# K1921VK01T register map
Vendor: NIIET; Series: K1921VKx; File version: 2.2
CPU: CM4 r0p1, little endian, MPU, FPU, 3 interrupt priority bits
Registers are 32-bit, read-write, reset 0x0 unless marked. A register's access mark holds for its fields unless they carry their own. Offsets are from the block's base; [hi:lo] are bit positions; {n}, {i} and the like mark numbered series; 'fields as' and 'values as' point back to an identical list.

## NT_COMMON_REG — Common block registers
Base 0x80030000
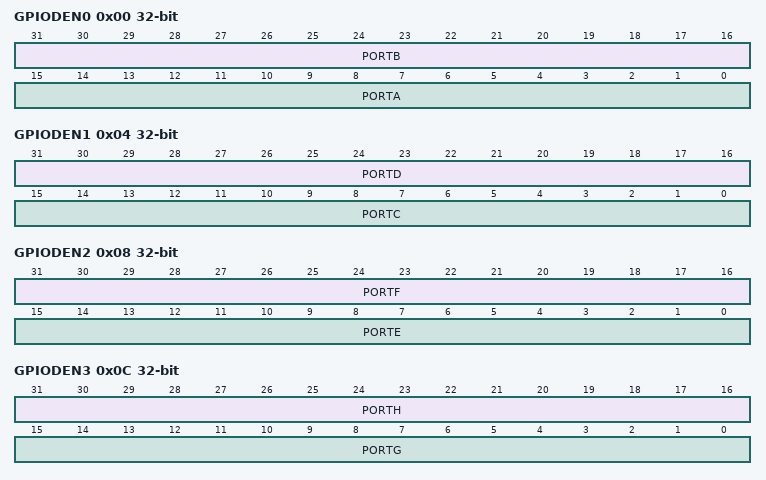
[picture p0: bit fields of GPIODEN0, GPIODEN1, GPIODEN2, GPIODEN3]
0x00 GPIODEN0 — Port A,B digital enable register
  [31:16] PORTB — Port B digital output (GPIO or ALTFUNC) enable
  [15:0] PORTA — Port A digital output (GPIO or ALTFUNC) enable
0x00 GPIODENA 16-bit (alternate view of GPIODEN0) — Port A digital enable register
  [15:0] PORTA — Port A digital output (GPIO or ALTFUNC) enable
0x02 GPIODENB 16-bit (alternate view of GPIODEN0) — Port B digital enable register
  [15:0] PORTB — Port B digital output (GPIO or ALTFUNC) enable
0x04 GPIODEN1 — Port C,D digital enable register
  [31:16] PORTD — Port D digital output (GPIO or ALTFUNC) enable
  [15:0] PORTC — Port C digital output (GPIO or ALTFUNC) enable
0x04 GPIODENC 16-bit (alternate view of GPIODEN1) — Port C digital enable register
  [15:0] PORTC — Port C digital output (GPIO or ALTFUNC) enable
0x06 GPIODEND 16-bit (alternate view of GPIODEN1) — Port D digital enable register
  [15:0] PORTD — Port D digital output (GPIO or ALTFUNC) enable
0x08 GPIODEN2 — Port E,F digital enable register
  [31:16] PORTF — Port F digital output (GPIO or ALTFUNC) enable
  [15:0] PORTE — Port E digital output (GPIO or ALTFUNC) enable
0x08 GPIODENE 16-bit (alternate view of GPIODEN2) — Port E digital enable register
  [15:0] PORTE — Port E digital output (GPIO or ALTFUNC) enable
0x0A GPIODENF 16-bit (alternate view of GPIODEN2) — Port F digital enable register
  [15:0] PORTF — Port F digital output (GPIO or ALTFUNC) enable
0x0C GPIODEN3 — Port G,H digital enable register
  [31:16] PORTH — Port H digital output (GPIO or ALTFUNC) enable
  [15:0] PORTG — Port G digital output (GPIO or ALTFUNC) enable
0x0C GPIODENG 16-bit (alternate view of GPIODEN3) — Port G digital enable register
  [15:0] PORTG — Port G digital output (GPIO or ALTFUNC) enable
0x0E GPIODENH 16-bit (alternate view of GPIODEN3) — Port H digital enable register
  [15:0] PORTH — Port H digital output (GPIO or ALTFUNC) enable
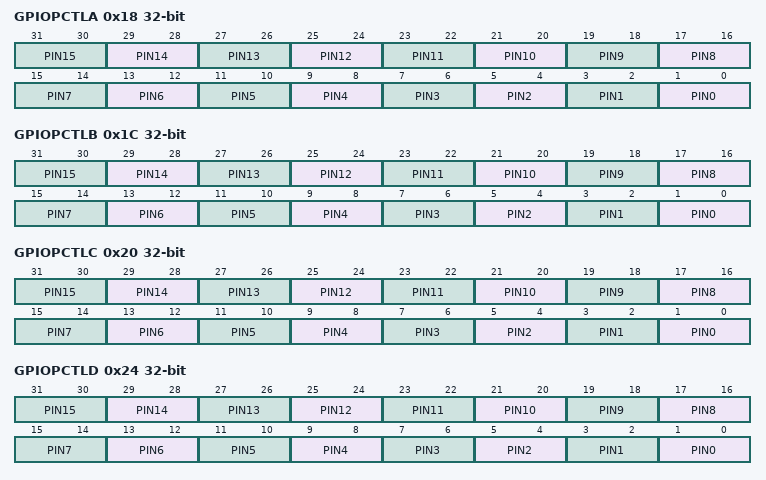
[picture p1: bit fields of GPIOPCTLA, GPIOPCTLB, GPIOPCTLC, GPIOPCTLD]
0x18 GPIOPCTLA — Port A alternative function selection register
  [all] fields
    0=AltFunc1 (first alternative function for pin); 1=AltFunc2 (second alternative function for pin); 2=AltFunc3 (third alternative function for pin)
  [2n+1:2n] PIN{n} (n=0..15) — Pin A{n} alternative function selection
0x1C GPIOPCTLB — Port B alternative function selection register
  [all] fields
    values as the fields of GPIOPCTLA
  [2n+1:2n] PIN{n} (n=0..15) — Pin B{n} alternative function selection
0x20 GPIOPCTLC — Port C alternative function selection register
  [all] fields
    values as the fields of GPIOPCTLA
  [2n+1:2n] PIN{n} (n=0..15) — Pin C{n} alternative function selection
0x24 GPIOPCTLD — Port D alternative function selection register
  [all] fields
    values as the fields of GPIOPCTLA
  [2n+1:2n] PIN{n} (n=0..15) — Pin D{n} alternative function selection
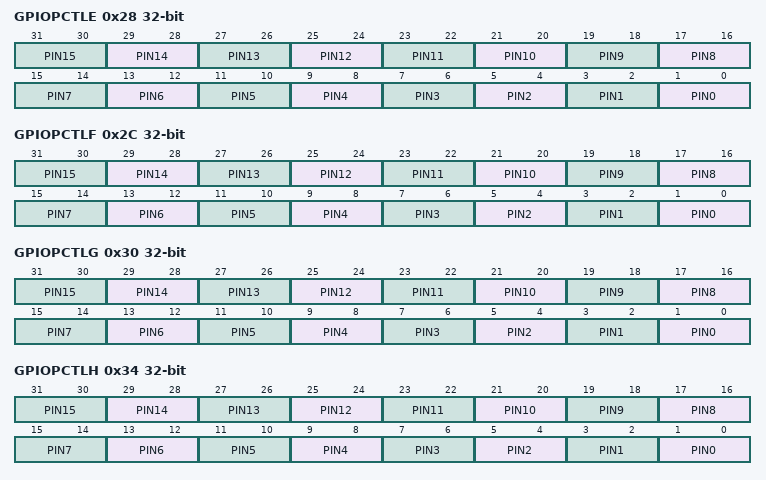
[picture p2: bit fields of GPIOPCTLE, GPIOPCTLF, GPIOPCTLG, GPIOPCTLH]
0x28 GPIOPCTLE — Port E alternative function selection register
  [all] fields
    values as the fields of GPIOPCTLA
  [2n+1:2n] PIN{n} (n=0..15) — Pin E{n} alternative function selection
0x2C GPIOPCTLF — Port F alternative function selection register
  [all] fields
    values as the fields of GPIOPCTLA
  [2n+1:2n] PIN{n} (n=0..15) — Pin F{n} alternative function selection
0x30 GPIOPCTLG — Port G alternative function selection register
  [all] fields
    values as the fields of GPIOPCTLA
  [2n+1:2n] PIN{n} (n=0..15) — Pin G{n} alternative function selection
0x34 GPIOPCTLH — Port H alternative function selection register
  [all] fields
    values as the fields of GPIOPCTLA
  [2n+1:2n] PIN{n} (n=0..15) — Pin H{n} alternative function selection
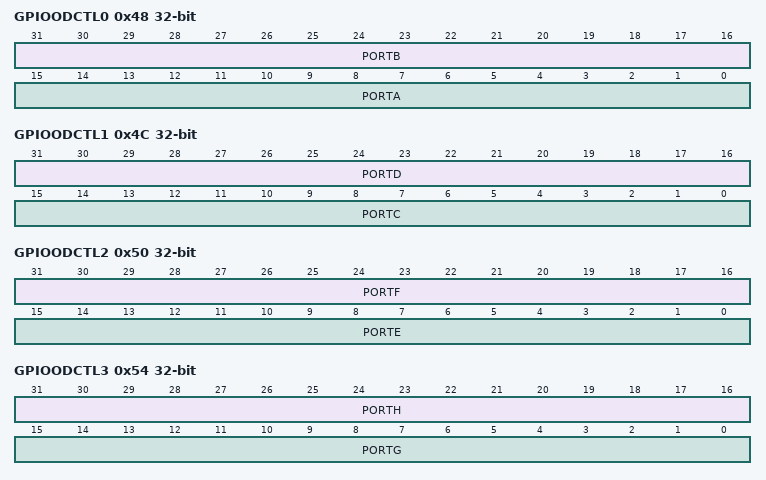
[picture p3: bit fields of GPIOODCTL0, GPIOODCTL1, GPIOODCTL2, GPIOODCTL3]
0x48 GPIOODCTL0 — Port A,B open-drain enable register
  [31:16] PORTB — Port B open-drain enable
  [15:0] PORTA — Port A open-drain enable
0x48 GPIOODCTLA 16-bit (alternate view of GPIOODCTL0) — Port A open-drain enable register
  [15:0] PORTA — Port A open-drain enable
0x4A GPIOODCTLB 16-bit (alternate view of GPIOODCTL0) — Port B open-drain enable register
  [15:0] PORTB — Port B open-drain enable
0x4C GPIOODCTL1 — Port C,D open-drain enable register
  [31:16] PORTD — Port D open-drain enable
  [15:0] PORTC — Port C open-drain enable
0x4C GPIOODCTLC 16-bit (alternate view of GPIOODCTL1) — Port C open-drain enable register
  [15:0] PORTC — Port C open-drain enable
0x4E GPIOODCTLD 16-bit (alternate view of GPIOODCTL1) — Port D open-drain enable register
  [15:0] PORTD — Port D open-drain enable
0x50 GPIOODCTL2 — Port E,F open-drain enable register
  [31:16] PORTF — Port F open-drain enable
  [15:0] PORTE — Port E open-drain enable
0x50 GPIOODCTLE 16-bit (alternate view of GPIOODCTL2) — Port E open-drain enable register
  [15:0] PORTE — Port E open-drain enable
0x52 GPIOODCTLF 16-bit (alternate view of GPIOODCTL2) — Port F open-drain enable register
  [15:0] PORTF — Port F open-drain enable
0x54 GPIOODCTL3 — Port G,H open-drain enable register
  [31:16] PORTH — Port H open-drain enable
  [15:0] PORTG — Port G open-drain enable
0x54 GPIOODCTLG 16-bit (alternate view of GPIOODCTL3) — Port G open-drain enable register
  [15:0] PORTG — Port G open-drain enable
0x56 GPIOODCTLH 16-bit (alternate view of GPIOODCTL3) — Port H open-drain enable register
  [15:0] PORTH — Port H open-drain enable
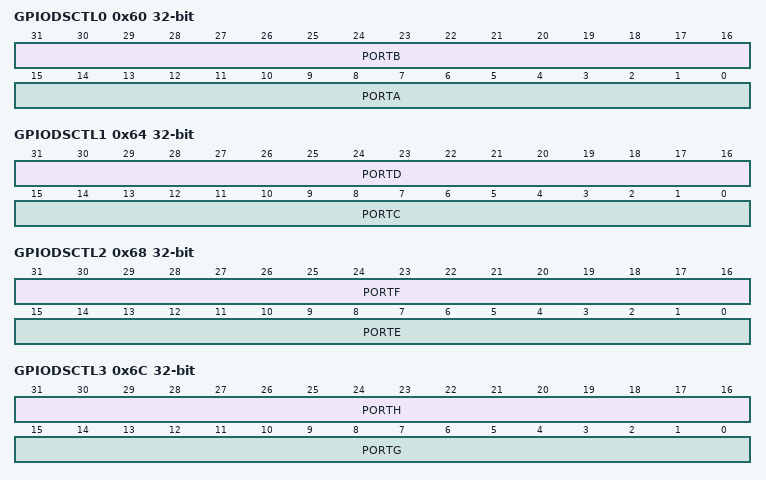
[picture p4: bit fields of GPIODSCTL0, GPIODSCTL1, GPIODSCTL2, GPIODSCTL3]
0x60 GPIODSCTL0 — Port A,B strength control register
  [31:16] PORTB — Port B strength control
  [15:0] PORTA — Port A strength control
0x60 GPIODSCTLA 16-bit (alternate view of GPIODSCTL0) — Port A strength control register
  [15:0] PORTA — Port A strength control
0x62 GPIODSCTLB 16-bit (alternate view of GPIODSCTL0) — Port B strength control register
  [15:0] PORTB — Port B strength control
0x64 GPIODSCTL1 — Port C,D strength control register
  [31:16] PORTD — Port D strength control
  [15:0] PORTC — Port C strength control
0x64 GPIODSCTLC 16-bit (alternate view of GPIODSCTL1) — Port C strength control register
  [15:0] PORTC — Port C strength control
0x66 GPIODSCTLD 16-bit (alternate view of GPIODSCTL1) — Port D strength control register
  [15:0] PORTD — Port D strength control
0x68 GPIODSCTL2 — Port E,F strength control register
  [31:16] PORTF — Port F strength control
  [15:0] PORTE — Port E strength control
0x68 GPIODSCTLE 16-bit (alternate view of GPIODSCTL2) — Port E strength control register
  [15:0] PORTE — Port E strength control
0x6A GPIODSCTLF 16-bit (alternate view of GPIODSCTL2) — Port F strength control register
  [15:0] PORTF — Port F strength control
0x6C GPIODSCTL3 — Port G,H strength control register
  [31:16] PORTH — Port H strength control
  [15:0] PORTG — Port G strength control
0x6C GPIODSCTLG 16-bit (alternate view of GPIODSCTL3) — Port G strength control register
  [15:0] PORTG — Port G strength control
0x6E GPIODSCTLH 16-bit (alternate view of GPIODSCTL3) — Port H strength control register
  [15:0] PORTH — Port H strength control
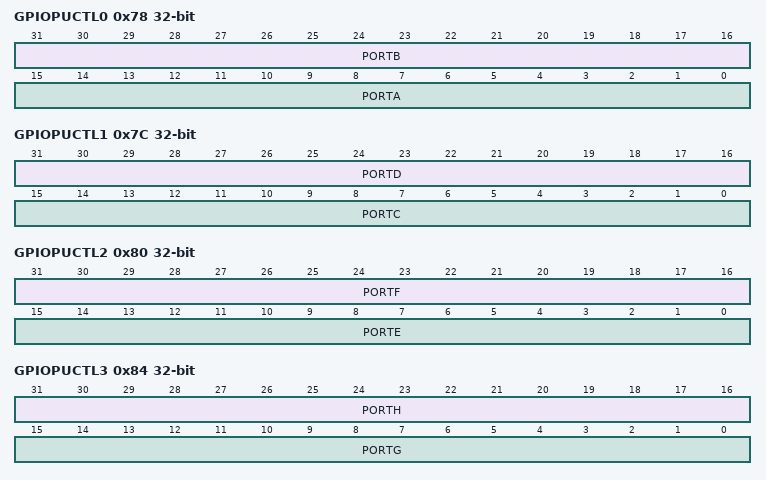
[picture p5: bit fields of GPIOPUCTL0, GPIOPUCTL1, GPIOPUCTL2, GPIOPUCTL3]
0x78 GPIOPUCTL0 — Port A,B pull-up enable register
  [31:16] PORTB — Port B pull-up enable
  [15:0] PORTA — Port A pull-up enable
0x78 GPIOPUCTLA 16-bit (alternate view of GPIOPUCTL0) — Port A pull-up enable register
  [15:0] PORTA — Port A pull-up enable
0x7A GPIOPUCTLB 16-bit (alternate view of GPIOPUCTL0) — Port B pull-up enable register
  [15:0] PORTB — Port B pull-up enable
0x7C GPIOPUCTL1 — Port C,D pull-up enable register
  [31:16] PORTD — Port D pull-up enable
  [15:0] PORTC — Port C pull-up enable
0x7C GPIOPUCTLC 16-bit (alternate view of GPIOPUCTL1) — Port C pull-up enable register
  [15:0] PORTC — Port C pull-up enable
0x7E GPIOPUCTLD 16-bit (alternate view of GPIOPUCTL1) — Port D pull-up enable register
  [15:0] PORTD — Port D pull-up enable
0x80 GPIOPUCTL2 — Port E,F pull-up enable register
  [31:16] PORTF — Port F pull-up enable
  [15:0] PORTE — Port E pull-up enable
0x80 GPIOPUCTLE 16-bit (alternate view of GPIOPUCTL2) — Port E pull-up enable register
  [15:0] PORTE — Port E pull-up enable
0x82 GPIOPUCTLF 16-bit (alternate view of GPIOPUCTL2) — Port F pull-up enable register
  [15:0] PORTF — Port F pull-up enable
0x84 GPIOPUCTL3 — Port G,H pull-up enable register
  [31:16] PORTH — Port H pull-up enable
  [15:0] PORTG — Port G pull-up enable
0x84 GPIOPUCTLG 16-bit (alternate view of GPIOPUCTL3) — Port G pull-up enable register
  [15:0] PORTG — Port G pull-up enable
0x86 GPIOPUCTLH 16-bit (alternate view of GPIOPUCTL3) — Port H pull-up enable register
  [15:0] PORTH — Port H pull-up enable
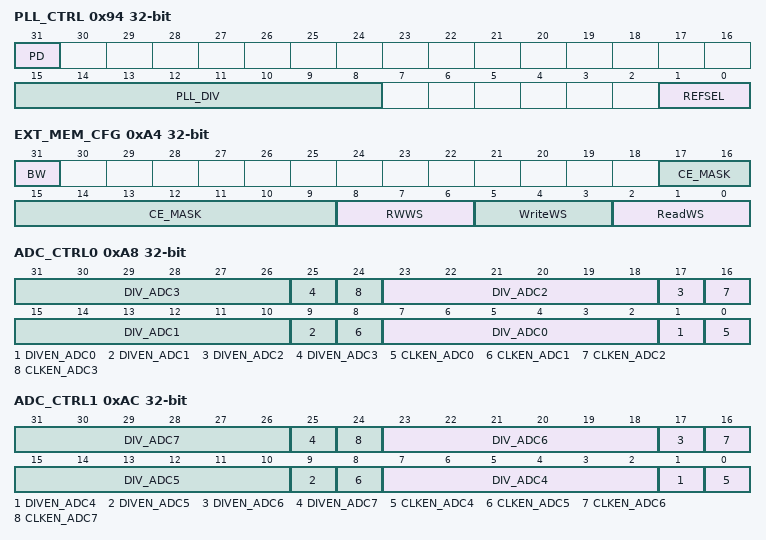
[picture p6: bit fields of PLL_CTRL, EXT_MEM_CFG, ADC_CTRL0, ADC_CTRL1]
0x94 PLL_CTRL — PLL control register
  [31] PD — PLL PowerDown mode enable
  [15:8] PLL_DIV — External divider for PLL output
  [1:0] REFSEL — PLL reference clk selection
    0=ExtOsc (tact signal from external oscillator); 1=USBClk (tact signal from USB clock(GPIO A0)); 2=USB60MHz (tact signal from USB 60 MHz); 3=ETH25MHz (tact signal from Ethernet 25 MHz)
0x98 PLL_OD — PLL output divider register
  [1:0] PLL_OD — Output divider "NO" control
    0=Disable (output PLL divider disabled); 1=Div2 (output PLL divider by 2 enabled); 3=Div4 (output PLL divider by 4 enabled)
0x9C PLL_NR — PLL reference divider register
  [4:0] R_PLL — PLL reference divider "NR = R_PLL+2"
0xA0 PLL_NF — PLL feedback divider register
  [8:0] F_PLL — PLL feedback divider "NF = F_PLL+2"
0xA4 EXT_MEM_CFG — External memory configuration register
  [31] BW — External memory bus width (8/16bit)
  [17:9] CE_MASK — CE1, OE1 address mask
  [8:6] RWWS — Pause wait state cycles value
  [5:3] WriteWS — Write wait state cycles value
  [2:0] ReadWS — Read wait state cycles value
0xA8 ADC_CTRL0 — ADC 0-3 clock control register
  [8n+7:8n+2] DIV_ADC{n} (n=0..3) — ADC{n} clk divider value
  [8n+1] DIVEN_ADC{n} (n=0..3) — ADC{n} clk divider enable
  [8n] CLKEN_ADC{n} (n=0..3) — ADC{n} clk enable
0xAC ADC_CTRL1 — ADC 4-7 clock control register
  [8n-25:8n-30] DIV_ADC{n} (n=4..7) — ADC{n} clk divider value
  [8n-31] DIVEN_ADC{n} (n=4..7) — ADC{n} clk divider enable
  [8n-32] CLKEN_ADC{n} (n=4..7) — ADC{n} clk enable
0xB0 PWM_SYNC — PWM prescalers sync register
  [8:0] TBCLKSYNC — PWM prescalers enable
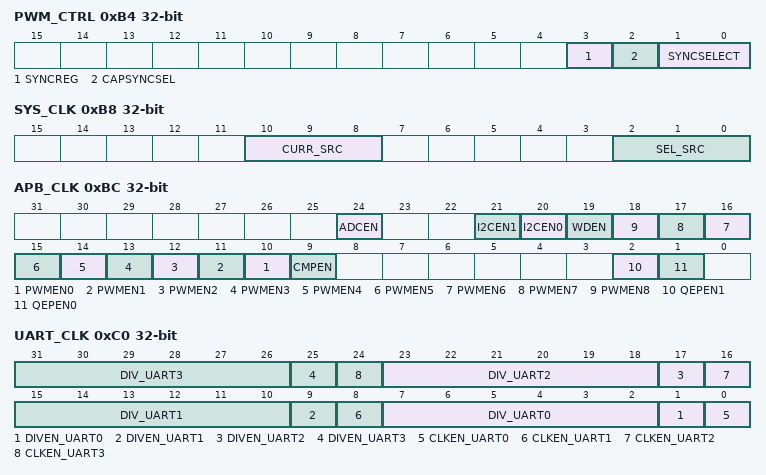
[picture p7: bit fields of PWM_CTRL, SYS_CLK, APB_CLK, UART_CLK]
0xB4 PWM_CTRL — PWM sync control register
  [3] SYNCREG — SYNCI pulse generation on PWM0 input
  [2] CAPSYNCSEL — CAP3 sync mode selection (from CAP2 or PWM0)
  [1:0] SYNCSELECT — PWM sync control register
0xB8 SYS_CLK — System clock control register
  [10:8] CURR_SRC ro — Current system clk source
    on read: 0=CPE (select POR clock or XI_OSC by input CPE); 1=POR (POR clock); 2=ExtOsc (external oscillator clock (XI_OSC)); 3=PLL (PLL clock); 4=PLLDiv (PLL clock with post-divider); 5=USB60MHz (USB clock 60 MHz); 6=USBClk (clock from input CLK_USB GPIO A0 (12/24 MHz)); 7=ETH25MHz (clock from external Ethernet clock GPIO B3 or GPIO A8)
  [2:0] SEL_SRC — System clk source selection
    0=CPE (select POR clock or XI_OSC by input CPE); 1=POR (POR clock); 2=ExtOsc (external oscillator clock (XI_OSC)); 3=PLL (PLL clock); 4=PLLDiv (PLL clock with post-divider); 5=USB60MHz (USB clock 60 MHz); 6=USBClk (clock from input CLK_USB GPIO A0 (12/24 MHz)); 7=ETH25MHz (clock from external Ethernet clock GPIO B3 or GPIO A8)
0xBC APB_CLK — Peripheral clock control register
  [24] ADCEN — ADC clk enable
  [21] I2CEN1 — I2C1 clk enable
  [20] I2CEN0 — I2C0 clk enable
  [19] WDEN — WDT clk enable
  [n+10] PWMEN{n} (n=0..8) — PWM{n} clk enable
  [9] CMPEN — Analog comparator clk enable
  [2] QEPEN1 — QEP1 clk enable
  [1] QEPEN0 — QEP0 clk enable
0xC0 UART_CLK — UART clock control register
  [8n+7:8n+2] DIV_UART{n} (n=0..3) — UART{n} clk divider value
  [8n+1] DIVEN_UART{n} (n=0..3) — UART{n} clk divider enable
  [8n] CLKEN_UART{n} (n=0..3) — UART{n} clk enable
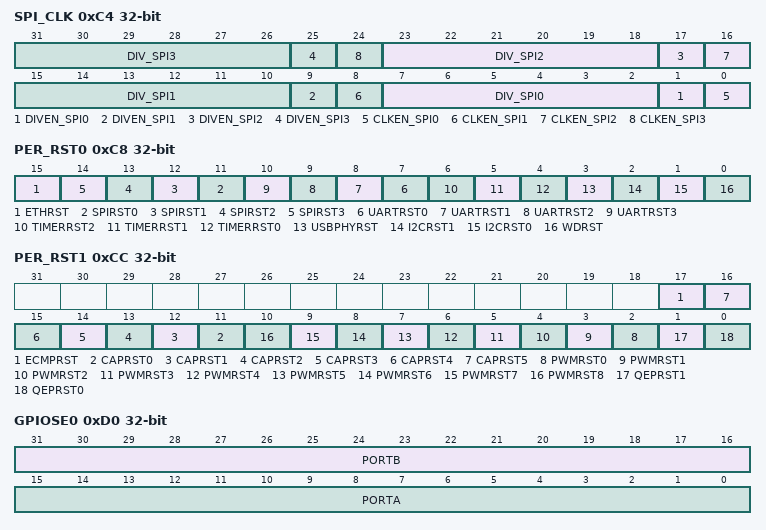
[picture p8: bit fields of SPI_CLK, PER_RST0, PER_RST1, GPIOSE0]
0xC4 SPI_CLK — SPI clock control register
  [8n+7:8n+2] DIV_SPI{n} (n=0..3) — SPI{n} clk divider value
  [8n+1] DIVEN_SPI{n} (n=0..3) — SPI{n} clk divider enable
  [8n] CLKEN_SPI{n} (n=0..3) — SPI{n} clk enable
0xC8 PER_RST0 — Peripheral reset register 0
  [15] ETHRST — Reset Ethernet
  [n+11] SPIRST{n} (n=0..3) — Reset SPI{n}
  [n+7] UARTRST{n} (n=0..3) — Reset UART{n}
  [6] TIMERRST2 — Reset TIMER2
  [5] TIMERRST1 — Reset TIMER1
  [4] TIMERRST0 — Reset TIMER0
  [3] USBPHYRST — Reset USB_PHY
  [2] I2CRST1 — Reset I2C1
  [1] I2CRST0 — Reset I2C0
  [0] WDRST — Reset WatchDog
0xCC PER_RST1 — Peripheral reset register 1
  [17] ECMPRST — Reset of analog comparator
  [n+11] CAPRST{n} (n=0..5) — Reset module CAP{n}
  [n+2] PWMRST{n} (n=0..8) — Reset module PWM{n}
  [1] QEPRST1 — Reset QEPR0
  [0] QEPRST0 — Reset QEPR0
0xD0 GPIOSE0 — Control register resynchronization input ports A, B
  [31:16] PORTB, [15:0] PORTA
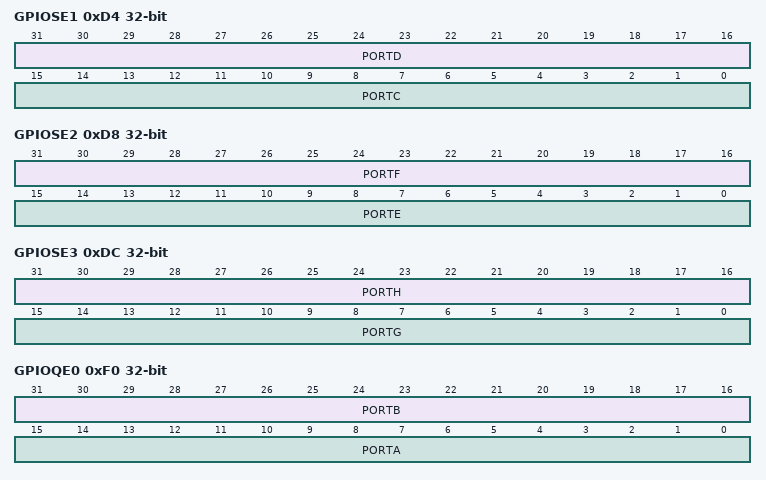
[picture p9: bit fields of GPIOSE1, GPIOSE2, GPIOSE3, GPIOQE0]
0xD4 GPIOSE1 — Control register resynchronization input ports C, D
  [31:16] PORTD, [15:0] PORTC
0xD8 GPIOSE2 — Control register resynchronization input ports E, F
  [31:16] PORTF, [15:0] PORTE
0xDC GPIOSE3 — Control register resynchronization input ports G, H
  [31:16] PORTH, [15:0] PORTG
0xF0 GPIOQE0 — Register filter settings input ports A, B
  [31:16] PORTB, [15:0] PORTA
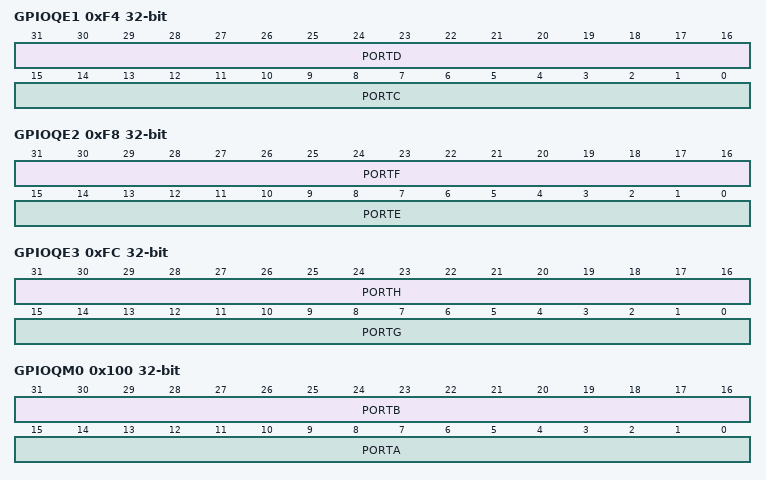
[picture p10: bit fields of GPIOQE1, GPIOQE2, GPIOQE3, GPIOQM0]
0xF4 GPIOQE1 — Register filter settings input ports C, D
  [31:16] PORTD, [15:0] PORTC
0xF8 GPIOQE2 — Register filter settings input ports E, F
  [31:16] PORTF, [15:0] PORTE
0xFC GPIOQE3 — Register filter settings input ports G, H
  [31:16] PORTH, [15:0] PORTG
0x100 GPIOQM0 — Register filter settings input ports A, B
  [31:16] PORTB, [15:0] PORTA
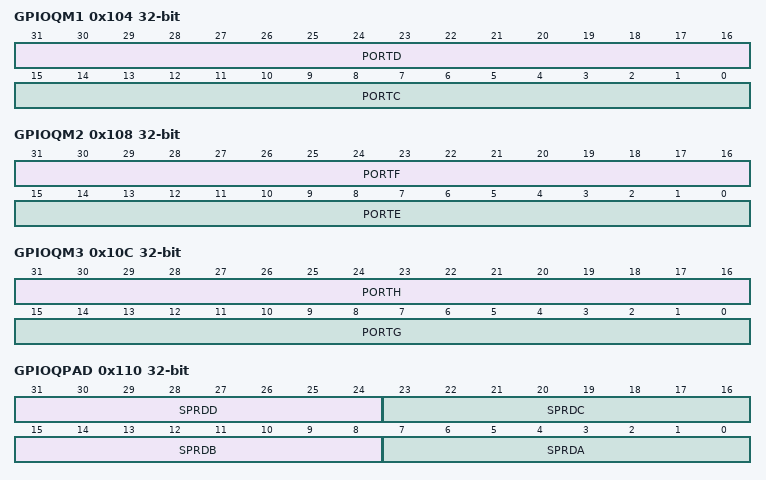
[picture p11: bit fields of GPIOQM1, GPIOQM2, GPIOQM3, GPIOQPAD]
0x104 GPIOQM1 — Register filter settings input ports C, D
  [31:16] PORTD, [15:0] PORTC
0x108 GPIOQM2 — Register filter settings input ports E, F
  [31:16] PORTF, [15:0] PORTE
0x10C GPIOQM3 — Register filter settings input ports G, H
  [31:16] PORTH, [15:0] PORTG
0x110 GPIOQPAD — Register filter settings input ports A, B, C, D
  [31:24] SPRDD, [23:16] SPRDC, [15:8] SPRDB, [7:0] SPRDA
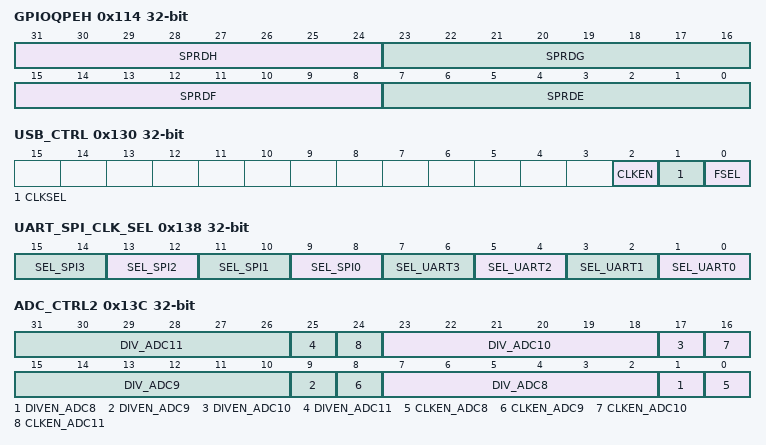
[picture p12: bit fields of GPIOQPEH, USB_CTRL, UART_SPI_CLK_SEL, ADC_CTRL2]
0x114 GPIOQPEH — Register filter settings input ports E, F, G, H
  [31:24] SPRDH, [23:16] SPRDG, [15:8] SPRDF, [7:0] SPRDE
0x130 USB_CTRL — Customize the USB PHY
  [2] CLKEN wo — Enable clk signal USBPHY
  [1] CLKSEL wo — Select of reference source USBPHY
  [0] FSEL — Frequency selection reference signal USBPHY (0- 12MHz; 1- 24MHz)
0x138 UART_SPI_CLK_SEL — Select source clk UART and SSP register
  [all] fields
    0=SysClk (system clock); 1=ExtOsc (external oscillator clock (XI_OSC)); 2=USBClk (USB clock from GPIO A0); 3=USB60MHz (USB clock 60 MHz)
  [2n+9:2n+8] SEL_SPI{n} (n=0..3) — Select source clk SPI{n}
  [2n+1:2n] SEL_UART{n} (n=0..3) — Select source clk UART{n}
0x13C ADC_CTRL2 — ADC control register 2
  [8n-57:8n-62] DIV_ADC{n} (n=8..11) — Divider clk ADC{n}
  [8n-63] DIVEN_ADC{n} (n=8..11) — Enable divider clk ADC{n}
  [8n-64] CLKEN_ADC{n} (n=8..11) — Enable clk ADC{n}
0x164 FLASH_FULL_ERASE — Full erase flash (user and boot) register
  [0] ERASE_FLASH
